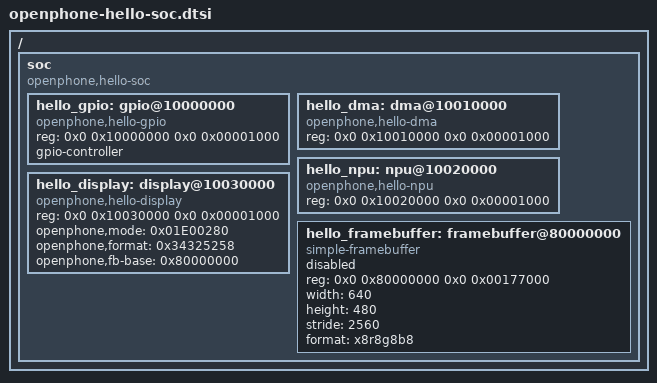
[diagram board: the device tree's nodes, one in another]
// SPDX-License-Identifier: GPL-2.0-only OR BSD-2-Clause
/*
 * OpenPhone hello SoC device-tree include file.
 *
 * Consumes the addresses defined in sw/platform/hello_platform_contract.json
 * via the matching offsets in
 * sw/linux/drivers/openphone/hello_platform_contract.h. Drop this file into
 * an external Linux tree at arch/<arch>/boot/dts/openphone/ and include it
 * from a board .dts that adds CPU(s), memory, an interrupt controller, and
 * the framebuffer reservation in /reserved-memory.
 *
 * This file deliberately uses /bits/ 64 raw cell counts (#address-cells = 2,
 * #size-cells = 2) so it can be reused on both 32-bit and 64-bit ports.
 */

/ {
	#address-cells = <2>;
	#size-cells = <2>;

	soc: soc {
		compatible = "openphone,hello-soc", "simple-bus";
		#address-cells = <2>;
		#size-cells = <2>;
		ranges;

		hello_gpio: gpio@10000000 {
			compatible = "openphone,hello-gpio";
			reg = <0x0 0x10000000 0x0 0x00001000>;
			gpio-controller;
			#gpio-cells = <2>;
			/* HELLO_PERIPHERAL_CONTROL_BASE; GPIO_OUT at +0x08 */
		};

		hello_dma: dma@10010000 {
			compatible = "openphone,hello-dma";
			reg = <0x0 0x10010000 0x0 0x00001000>;
			interrupt-names = "IRQ_DMA";
			/* HELLO_DMA_BASE */
		};

		hello_npu: npu@10020000 {
			compatible = "openphone,hello-npu";
			reg = <0x0 0x10020000 0x0 0x00001000>;
			interrupt-names = "IRQ_NPU";
			/* HELLO_NPU_BASE */
		};

		hello_display: display@10030000 {
			compatible = "openphone,hello-display";
			reg = <0x0 0x10030000 0x0 0x00001000>;
			interrupt-names = "IRQ_VSYNC";
			openphone,mode   = <0x01E00280>; /* 640x480 */
			openphone,format = <0x34325258>; /* XR24 */
			openphone,fb-base = <0x80000000>;
			/* HELLO_DISPLAY_BASE */
		};

		hello_framebuffer: framebuffer@80000000 {
			compatible = "simple-framebuffer";
			reg = <0x0 0x80000000 0x0 0x00177000>;
			width = <640>;
			height = <480>;
			stride = <2560>;
			format = "x8r8g8b8";
			status = "disabled";
			/* Enable from the board .dts once /reserved-memory
			 * carves the framebuffer out of DRAM.
			 */
		};
	};
};
